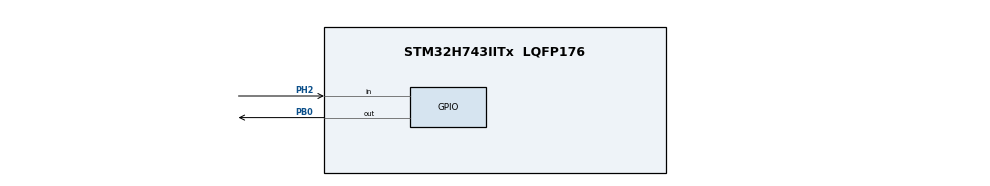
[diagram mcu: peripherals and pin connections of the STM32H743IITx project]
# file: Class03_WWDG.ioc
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Mcu.Family=STM32H7
Mcu.Name=STM32H743IITx
Mcu.Package=LQFP176
NVIC.PriorityGroup=NVIC_PRIORITYGROUP_4
NVIC.WWDG_IRQn=true\:3\:0\:true\:true\:true\:1\:true
PB0.GPIO_ModeDefaultOutputPP=GPIO_MODE_OUTPUT_OD
PB0.GPIO_Speed=GPIO_SPEED_FREQ_VERY_HIGH
PB0.PinState=GPIO_PIN_SET
PB0.Signal=GPIO_Output
PH0-OSC_IN.Mode=HSE-External-Oscillator
PH0-OSC_IN.Signal=RCC_OSC_IN
PH1-OSC_OUT.Mode=HSE-External-Oscillator
PH1-OSC_OUT.Signal=RCC_OSC_OUT
PH2.GPIO_PuPd=GPIO_PULLUP
PH2.Signal=GPIO_Input
ProjectManager.HeapSize=0x200
ProjectManager.StackSize=0x400
ProjectManager.TargetToolchain=MDK-ARM V5
RCC.ADCFreq_Value=50390625
RCC.APB1Freq_Value=100000000
RCC.APB2Freq_Value=100000000
RCC.APB3Freq_Value=12500000
RCC.APB4Freq_Value=100000000
RCC.CortexFreq_Value=400000000
RCC.D1PPRE=RCC_APB3_DIV16
RCC.D2PPRE1=RCC_APB1_DIV2
RCC.D2PPRE2=RCC_APB2_DIV2
RCC.D3PPRE=RCC_APB4_DIV2
RCC.DIVM1=2
RCC.DIVN1=64
RCC.HCLKFreq_Value=200000000
RCC.HPRE=RCC_HCLK_DIV2
RCC.PLLSourceVirtual=RCC_PLLSOURCE_HSE
RCC.SYSCLKFreq_VALUE=400000000
RCC.SYSCLKSource=RCC_SYSCLKSOURCE_PLLCLK
RCC.USBFreq_Value=400000000
VP_WWDG1_VS_WWDG.Mode=WWDG_Activate
WWDG1.Counter=127
WWDG1.EWIMode=WWDG_EWI_ENABLE
WWDG1.Prescaler=WWDG_PRESCALER_128
board=custom

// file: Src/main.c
/**
  ******************************************************************************
  * @file           : main.c
  * @brief          : Main program body
  ******************************************************************************
  ** This notice applies to any and all portions of this file
  * that are not between comment pairs USER CODE BEGIN and
  * USER CODE END. Other portions of this file, whether
  * inserted by the user or by software development tools
  * are owned by their respective copyright owners.
  *
  * COPYRIGHT(c) 2018 STMicroelectronics
  *
  * Redistribution and use in source and binary forms, with or without modification,
  * are permitted provided that the following conditions are met:
  *   1. Redistributions of source code must retain the above copyright notice,
  *      this list of conditions and the following disclaimer.
  *   2. Redistributions in binary form must reproduce the above copyright notice,
  *      this list of conditions and the following disclaimer in the documentation
  *      and/or other materials provided with the distribution.
  *   3. Neither the name of STMicroelectronics nor the names of its contributors
  *      may be used to endorse or promote products derived from this software
  *      without specific prior written permission.
  *
  * THIS SOFTWARE IS PROVIDED BY THE COPYRIGHT HOLDERS AND CONTRIBUTORS "AS IS"
  * AND ANY EXPRESS OR IMPLIED WARRANTIES, INCLUDING, BUT NOT LIMITED TO, THE
  * IMPLIED WARRANTIES OF MERCHANTABILITY AND FITNESS FOR A PARTICULAR PURPOSE ARE
  * DISCLAIMED. IN NO EVENT SHALL THE COPYRIGHT HOLDER OR CONTRIBUTORS BE LIABLE
  * FOR ANY DIRECT, INDIRECT, INCIDENTAL, SPECIAL, EXEMPLARY, OR CONSEQUENTIAL
  * DAMAGES (INCLUDING, BUT NOT LIMITED TO, PROCUREMENT OF SUBSTITUTE GOODS OR
  * SERVICES; LOSS OF USE, DATA, OR PROFITS; OR BUSINESS INTERRUPTION) HOWEVER
  * CAUSED AND ON ANY THEORY OF LIABILITY, WHETHER IN CONTRACT, STRICT LIABILITY,
  * OR TORT (INCLUDING NEGLIGENCE OR OTHERWISE) ARISING IN ANY WAY OUT OF THE USE
  * OF THIS SOFTWARE, EVEN IF ADVISED OF THE POSSIBILITY OF SUCH DAMAGE.
  *
  ******************************************************************************
  */
#include "main.h"
#include "stm32h7xx_hal.h"

WWDG_HandleTypeDef hwwdg1;

/* USER CODE BEGIN PV */
/* Private variables ---------------------------------------------------------*/

/* USER CODE END PV */

void SystemClock_Config(void);
static void MX_GPIO_Init(void);
static void MX_WWDG1_Init(void);
static void MX_NVIC_Init(void);

/* USER CODE BEGIN PFP */
/* Private function prototypes -----------------------------------------------*/

/* USER CODE END PFP */

int main(void)
{

  /* MCU Configuration----------------------------------------------------------*/

  /* Reset of all peripherals, Initializes the Flash interface and the Systick. */
  HAL_Init();

  /* Configure the system clock */
  SystemClock_Config();

  /* Initialize all configured peripherals */
  MX_GPIO_Init();
  MX_WWDG1_Init();

  /* Initialize interrupts */
  MX_NVIC_Init();

  /* Infinite loop */
  while (1)
  {

  /* USER CODE BEGIN 3 */
		if(!HAL_GPIO_ReadPin(GPIOH,GPIO_PIN_2))
		{
			HAL_WWDG_Refresh(&hwwdg1);
		}
		HAL_Delay(200);
		HAL_GPIO_TogglePin(GPIOB,GPIO_PIN_0);
  }
  /* USER CODE END 3 */

}

void SystemClock_Config(void)
{

  RCC_OscInitTypeDef RCC_OscInitStruct;
  RCC_ClkInitTypeDef RCC_ClkInitStruct;

    /**Supply configuration update enable
    */
  MODIFY_REG(PWR->CR3, PWR_CR3_SCUEN, 0);

    /**Configure the main internal regulator output voltage
    */
  __HAL_PWR_VOLTAGESCALING_CONFIG(PWR_REGULATOR_VOLTAGE_SCALE1);

  while ((PWR->D3CR & (PWR_D3CR_VOSRDY)) != PWR_D3CR_VOSRDY)
  {

  }
    /**Initializes the CPU, AHB and APB busses clocks
    */
  RCC_OscInitStruct.OscillatorType = RCC_OSCILLATORTYPE_HSE;
  RCC_OscInitStruct.HSEState = RCC_HSE_ON;
  RCC_OscInitStruct.PLL.PLLState = RCC_PLL_ON;
  RCC_OscInitStruct.PLL.PLLSource = RCC_PLLSOURCE_HSE;
  RCC_OscInitStruct.PLL.PLLM = 2;
  RCC_OscInitStruct.PLL.PLLN = 64;
  RCC_OscInitStruct.PLL.PLLP = 2;
  RCC_OscInitStruct.PLL.PLLQ = 2;
  RCC_OscInitStruct.PLL.PLLR = 2;
  RCC_OscInitStruct.PLL.PLLRGE = RCC_PLL1VCIRANGE_3;
  RCC_OscInitStruct.PLL.PLLVCOSEL = RCC_PLL1VCOWIDE;
  RCC_OscInitStruct.PLL.PLLFRACN = 0;
  if (HAL_RCC_OscConfig(&RCC_OscInitStruct) != HAL_OK)
  {
    _Error_Handler(__FILE__, __LINE__);
  }

    /**Initializes the CPU, AHB and APB busses clocks
    */
  RCC_ClkInitStruct.ClockType = RCC_CLOCKTYPE_HCLK|RCC_CLOCKTYPE_SYSCLK
                              |RCC_CLOCKTYPE_PCLK1|RCC_CLOCKTYPE_PCLK2
                              |RCC_CLOCKTYPE_D3PCLK1|RCC_CLOCKTYPE_D1PCLK1;
  RCC_ClkInitStruct.SYSCLKSource = RCC_SYSCLKSOURCE_PLLCLK;
  RCC_ClkInitStruct.SYSCLKDivider = RCC_SYSCLK_DIV1;
  RCC_ClkInitStruct.AHBCLKDivider = RCC_HCLK_DIV2;
  RCC_ClkInitStruct.APB3CLKDivider = RCC_APB3_DIV16;
  RCC_ClkInitStruct.APB1CLKDivider = RCC_APB1_DIV2;
  RCC_ClkInitStruct.APB2CLKDivider = RCC_APB2_DIV2;
  RCC_ClkInitStruct.APB4CLKDivider = RCC_APB4_DIV2;

  if (HAL_RCC_ClockConfig(&RCC_ClkInitStruct, FLASH_LATENCY_2) != HAL_OK)
  {
    _Error_Handler(__FILE__, __LINE__);
  }

    /**Configure the Systick interrupt time
    */
  HAL_SYSTICK_Config(SystemCoreClock/1000);

    /**Configure the Systick
    */
  HAL_SYSTICK_CLKSourceConfig(SYSTICK_CLKSOURCE_HCLK);

  /* SysTick_IRQn interrupt configuration */
  HAL_NVIC_SetPriority(SysTick_IRQn, 0, 0);
}

/**
  * @brief NVIC Configuration.
  * @retval None
  */
static void MX_NVIC_Init(void)
{
  /* WWDG_IRQn interrupt configuration */
  HAL_NVIC_SetPriority(WWDG_IRQn, 3, 0);
  HAL_NVIC_EnableIRQ(WWDG_IRQn);
}

/* WWDG1 init function */
static void MX_WWDG1_Init(void)
{

  hwwdg1.Instance = WWDG1;
  hwwdg1.Init.Prescaler = WWDG_PRESCALER_128;
  hwwdg1.Init.Window = 64;
  hwwdg1.Init.Counter = 127;
  hwwdg1.Init.EWIMode = WWDG_EWI_ENABLE;
  if (HAL_WWDG_Init(&hwwdg1) != HAL_OK)
  {
    _Error_Handler(__FILE__, __LINE__);
  }

}

/** Configure pins as
        * Analog
        * Input
        * Output
        * EVENT_OUT
        * EXTI
*/
static void MX_GPIO_Init(void)
{

  GPIO_InitTypeDef GPIO_InitStruct;

  /* GPIO Ports Clock Enable */
  __HAL_RCC_GPIOH_CLK_ENABLE();
  __HAL_RCC_GPIOB_CLK_ENABLE();

  /*Configure GPIO pin Output Level */
  HAL_GPIO_WritePin(GPIOB, GPIO_PIN_0, GPIO_PIN_SET);

  /*Configure GPIO pin : PH2 */
  GPIO_InitStruct.Pin = GPIO_PIN_2;
  GPIO_InitStruct.Mode = GPIO_MODE_INPUT;
  GPIO_InitStruct.Pull = GPIO_PULLUP;
  HAL_GPIO_Init(GPIOH, &GPIO_InitStruct);

  /*Configure GPIO pin : PB0 */
  GPIO_InitStruct.Pin = GPIO_PIN_0;
  GPIO_InitStruct.Mode = GPIO_MODE_OUTPUT_OD;
  GPIO_InitStruct.Pull = GPIO_NOPULL;
  GPIO_InitStruct.Speed = GPIO_SPEED_FREQ_VERY_HIGH;
  HAL_GPIO_Init(GPIOB, &GPIO_InitStruct);

}

void _Error_Handler(char *file, int line)
{
  while(1)
  {
  }
}

/************************ (C) COPYRIGHT STMicroelectronics *****END OF FILE****/
